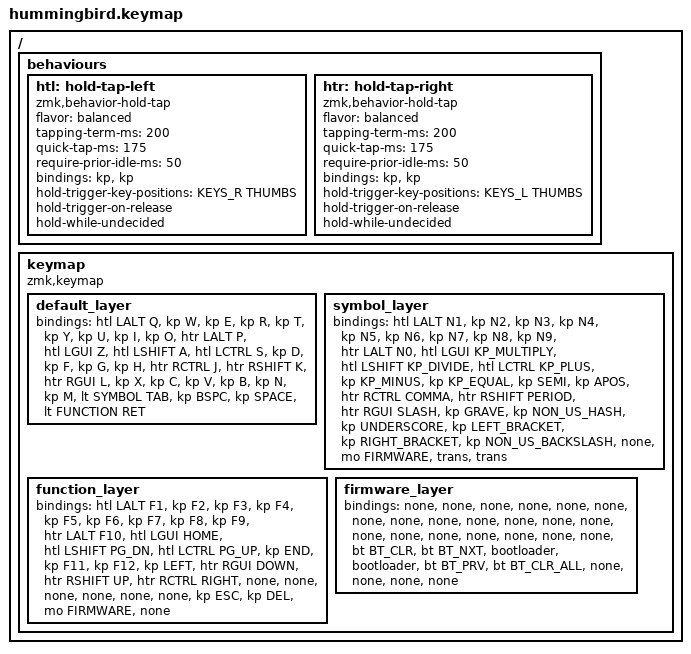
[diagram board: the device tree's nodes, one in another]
#include <behaviors.dtsi>
#include <dt-bindings/zmk/bt.h>
#include <dt-bindings/zmk/keys.h>

#define KEYS_L  0  1  2  3  4  5  6  7  8  9 10 11 12
#define KEYS_R 19 20 21 22 23 24 25 26 27 28 29 30 31
#define THUMBS 13 14 15 16 17 18

#define DEFAULT  0
#define SYMBOL   1
#define FUNCTION 2
#define FIRMWARE 3

/ {
    behaviours {
        htl: hold-tap-left {
            compatible = "zmk,behavior-hold-tap";
            #binding-cells = <2>;
            flavor = "balanced";
            tapping-term-ms = <200>;
            quick-tap-ms = <175>;
            require-prior-idle-ms = <50>;
            bindings = <&kp>, <&kp>;
            hold-trigger-key-positions = <KEYS_R THUMBS>;
            hold-trigger-on-release;
            hold-while-undecided;
        };

        htr: hold-tap-right {
            compatible = "zmk,behavior-hold-tap";
            #binding-cells = <2>;
            flavor = "balanced";
            tapping-term-ms = <200>;
            quick-tap-ms = <175>;
            require-prior-idle-ms = <50>;
            bindings = <&kp>, <&kp>;
            hold-trigger-key-positions = <KEYS_L THUMBS>;
            hold-trigger-on-release;
            hold-while-undecided;
        };
    };

    keymap {
        compatible = "zmk,keymap";

        default_layer {
            bindings = <
                &htl LALT Q
                &kp W
                &kp E
                &kp R
                &kp T
                &kp Y
                &kp U
                &kp I
                &kp O
                &htr LALT P

                &htl LGUI Z
                &htl LSHIFT A
                &htl LCTRL S
                &kp D
                &kp F
                &kp G
                &kp H
                &htr RCTRL J
                &htr RSHIFT K
                &htr RGUI L

                &kp X
                &kp C
                &kp V
                &kp B
                &kp N
                &kp M

                &lt SYMBOL TAB
                &kp BSPC
                &kp SPACE
                &lt FUNCTION RET
            >;
        };

        symbol_layer {
            bindings = <
                &htl LALT N1
                &kp N2
                &kp N3
                &kp N4
                &kp N5
                &kp N6
                &kp N7
                &kp N8
                &kp N9
                &htr LALT N0

                &htl LGUI KP_MULTIPLY 
                &htl LSHIFT KP_DIVIDE
                &htl LCTRL KP_PLUS 
                &kp KP_MINUS
                &kp KP_EQUAL
                &kp SEMI
                &kp APOS
                &htr RCTRL COMMA
                &htr RSHIFT PERIOD
                &htr RGUI SLASH

                &kp GRAVE
                &kp NON_US_HASH
                &kp UNDERSCORE 
                &kp LEFT_BRACKET
                &kp RIGHT_BRACKET
                &kp NON_US_BACKSLASH

                &none
                &mo FIRMWARE
                &trans
                &trans
            >;            
        };

        function_layer {
            bindings = <
                &htl LALT F1
                &kp F2
                &kp F3
                &kp F4
                &kp F5
                &kp F6
                &kp F7
                &kp F8
                &kp F9
                &htr LALT F10

                &htl LGUI HOME
                &htl LSHIFT PG_DN
                &htl LCTRL PG_UP
                &kp END
                &kp F11
                &kp F12
                &kp LEFT
                &htr RGUI DOWN
                &htr RSHIFT UP
                &htr RCTRL RIGHT

                &none
                &none
                &none
                &none
                &none
                &none

                &kp ESC
                &kp DEL
                &mo FIRMWARE
                &none
            >;
        };

        firmware_layer {
            bindings = <
                &none
                &none
                &none
                &none
                &none
                &none
                &none
                &none
                &none
                &none

                &none
                &none
                &none
                &none
                &none
                &none
                &none
                &none
                &none
                &none

                &bt BT_CLR
                &bt BT_NXT
                &bootloader
                &bootloader
                &bt BT_PRV
                &bt BT_CLR_ALL

                &none
                &none
                &none
                &none
            >;
        };
    };
};
